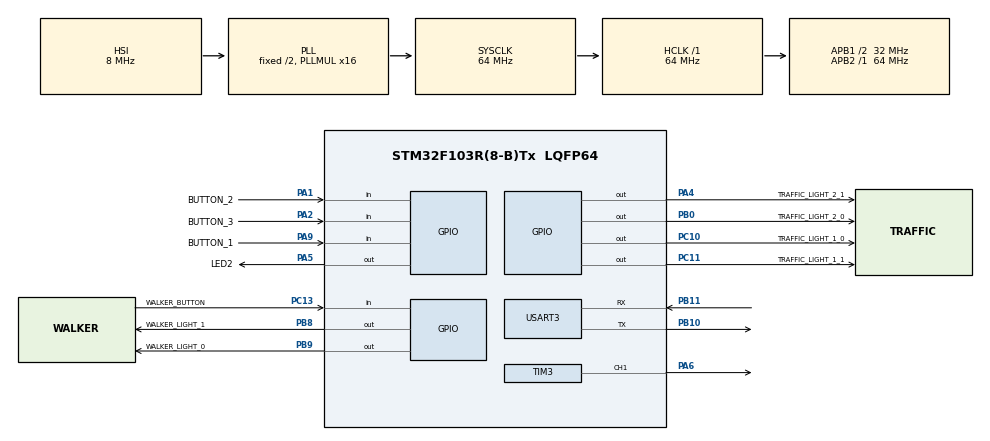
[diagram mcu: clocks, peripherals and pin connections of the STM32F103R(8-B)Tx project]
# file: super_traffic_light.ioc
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Mcu.Family=STM32F1
Mcu.Name=STM32F103R(8-B)Tx
Mcu.Package=LQFP64
NVIC.PriorityGroup=NVIC_PRIORITYGROUP_4
NVIC.TIM2_IRQn=true\:0\:0\:false\:false\:true\:true\:true
NVIC.USART3_IRQn=true\:0\:0\:false\:false\:true\:true\:true
PA1.GPIO_Label=BUTTON_2
PA1.Signal=GPIO_Input
PA13.Mode=Serial_Wire
PA13.Signal=SYS_JTMS-SWDIO
PA14.Mode=Serial_Wire
PA14.Signal=SYS_JTCK-SWCLK
PA2.GPIO_Label=BUTTON_3
PA2.Signal=GPIO_Input
PA4.GPIO_Label=TRAFFIC_LIGHT_2_1
PA4.Signal=GPIO_Output
PA5.GPIO_Label=LED2
PA5.Signal=GPIO_Output
PA6.Signal=S_TIM3_CH1
PA9.GPIO_Label=BUTTON_1
PA9.Signal=GPIO_Input
PB0.GPIO_Label=TRAFFIC_LIGHT_2_0
PB0.Signal=GPIO_Output
PB10.Mode=Asynchronous
PB10.Signal=USART3_TX
PB11.Mode=Asynchronous
PB11.Signal=USART3_RX
PB8.GPIO_Label=WALKER_LIGHT_1
PB8.Signal=GPIO_Output
PB9.GPIO_Label=WALKER_LIGHT_0
PB9.Signal=GPIO_Output
PC10.GPIO_Label=TRAFFIC_LIGHT_1_0
PC10.Signal=GPIO_Output
PC11.GPIO_Label=TRAFFIC_LIGHT_1_1
PC11.Signal=GPIO_Output
PC13-TAMPER-RTC.GPIO_Label=WALKER_BUTTON
PC13-TAMPER-RTC.Signal=GPIO_Input
PD0-OSC_IN.Mode=HSE-External-Oscillator
PD0-OSC_IN.Signal=RCC_OSC_IN
PD1-OSC_OUT.Mode=HSE-External-Oscillator
PD1-OSC_OUT.Signal=RCC_OSC_OUT
ProjectManager.HeapSize=0x200
ProjectManager.StackSize=0x400
ProjectManager.TargetToolchain=STM32CubeIDE
RCC.AHBFreq_Value=64000000
RCC.APB1CLKDivider=RCC_HCLK_DIV2
RCC.APB1Freq_Value=32000000
RCC.APB1TimFreq_Value=64000000
RCC.APB2Freq_Value=64000000
RCC.APB2TimFreq_Value=64000000
RCC.HCLKFreq_Value=64000000
RCC.PLLMUL=RCC_PLL_MUL16
RCC.SYSCLKFreq_VALUE=64000000
RCC.SYSCLKSource=RCC_SYSCLKSOURCE_PLLCLK
RCC.USBFreq_Value=64000000
SH.S_TIM3_CH1.0=TIM3_CH1,PWM Generation1 CH1
TIM2.CounterMode=TIM_COUNTERMODE_UP
TIM2.Period=999
TIM2.Prescaler=639
TIM3.Channel-PWM\ Generation1\ CH1=TIM_CHANNEL_1
TIM3.Period=999
TIM3.Prescaler=639
USART3.VirtualMode=VM_ASYNC
VP_TIM2_VS_ClockSourceINT.Mode=Internal
VP_TIM3_VS_ClockSourceINT.Mode=Internal
board=custom

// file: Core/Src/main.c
/* USER CODE BEGIN Header */
/**
  ******************************************************************************
  * @file           : main.c
  * @brief          : Main program body
  ******************************************************************************
  * @attention
  *
  * <h2><center>&copy; Copyright (c) 2023 STMicroelectronics.
  * All rights reserved.</center></h2>
  *
  * This software component is licensed by ST under BSD 3-Clause license,
  * the "License"; You may not use this file except in compliance with the
  * License. You may obtain a copy of the License at:
  *                        opensource.org/licenses/BSD-3-Clause
  *
  ******************************************************************************
  */
/* USER CODE END Header */
#include "main.h"

TIM_HandleTypeDef htim2;
TIM_HandleTypeDef htim3;

UART_HandleTypeDef huart3;

void SystemClock_Config(void);
static void MX_GPIO_Init(void);
static void MX_TIM2_Init(void);
static void MX_TIM3_Init(void);
static void MX_USART3_UART_Init(void);

int main(void)
{

  /* MCU Configuration--------------------------------------------------------*/

  /* Reset of all peripherals, Initializes the Flash interface and the Systick. */
  HAL_Init();

  /* USER CODE BEGIN Init */
timerInnit();
buttonInnit();
  /* USER CODE END Init */

  /* Configure the system clock */
  SystemClock_Config();

  /* Initialize all configured peripherals */
  MX_GPIO_Init();
  MX_TIM2_Init();
  MX_TIM3_Init();
  MX_USART3_UART_Init();
  /* USER CODE BEGIN 2 */
  HAL_TIM_Base_Start_IT (& htim2 );
  HAL_TIM_PWM_Start(&htim3, TIM_CHANNEL_1);
//  __HAL_UART_ENABLE_IT(&huart2, UART_IT_RXNE);

  /* USER CODE END 2 */

  /* Infinite loop */
  /* USER CODE BEGIN WHILE */
  while (1)
  {

	  fsm_manual_run();

    /* USER CODE END WHILE */

  }
}

void SystemClock_Config(void)
{
  RCC_OscInitTypeDef RCC_OscInitStruct = {0};
  RCC_ClkInitTypeDef RCC_ClkInitStruct = {0};

  /** Initializes the RCC Oscillators according to the specified parameters
  * in the RCC_OscInitTypeDef structure.
  */
  RCC_OscInitStruct.OscillatorType = RCC_OSCILLATORTYPE_HSI;
  RCC_OscInitStruct.HSIState = RCC_HSI_ON;
  RCC_OscInitStruct.HSICalibrationValue = RCC_HSICALIBRATION_DEFAULT;
  RCC_OscInitStruct.PLL.PLLState = RCC_PLL_ON;
  RCC_OscInitStruct.PLL.PLLSource = RCC_PLLSOURCE_HSI_DIV2;
  RCC_OscInitStruct.PLL.PLLMUL = RCC_PLL_MUL16;
  if (HAL_RCC_OscConfig(&RCC_OscInitStruct) != HAL_OK)
  {
    Error_Handler();
  }
  /** Initializes the CPU, AHB and APB buses clocks
  */
  RCC_ClkInitStruct.ClockType = RCC_CLOCKTYPE_HCLK|RCC_CLOCKTYPE_SYSCLK
                              |RCC_CLOCKTYPE_PCLK1|RCC_CLOCKTYPE_PCLK2;
  RCC_ClkInitStruct.SYSCLKSource = RCC_SYSCLKSOURCE_PLLCLK;
  RCC_ClkInitStruct.AHBCLKDivider = RCC_SYSCLK_DIV1;
  RCC_ClkInitStruct.APB1CLKDivider = RCC_HCLK_DIV2;
  RCC_ClkInitStruct.APB2CLKDivider = RCC_HCLK_DIV1;

  if (HAL_RCC_ClockConfig(&RCC_ClkInitStruct, FLASH_LATENCY_2) != HAL_OK)
  {
    Error_Handler();
  }
}

static void MX_TIM2_Init(void)
{

  TIM_ClockConfigTypeDef sClockSourceConfig = {0};
  TIM_MasterConfigTypeDef sMasterConfig = {0};

  htim2.Instance = TIM2;
  htim2.Init.Prescaler = 639;
  htim2.Init.CounterMode = TIM_COUNTERMODE_UP;
  htim2.Init.Period = 999;
  htim2.Init.ClockDivision = TIM_CLOCKDIVISION_DIV1;
  htim2.Init.AutoReloadPreload = TIM_AUTORELOAD_PRELOAD_DISABLE;
  if (HAL_TIM_Base_Init(&htim2) != HAL_OK)
  {
    Error_Handler();
  }
  sClockSourceConfig.ClockSource = TIM_CLOCKSOURCE_INTERNAL;
  if (HAL_TIM_ConfigClockSource(&htim2, &sClockSourceConfig) != HAL_OK)
  {
    Error_Handler();
  }
  sMasterConfig.MasterOutputTrigger = TIM_TRGO_RESET;
  sMasterConfig.MasterSlaveMode = TIM_MASTERSLAVEMODE_DISABLE;
  if (HAL_TIMEx_MasterConfigSynchronization(&htim2, &sMasterConfig) != HAL_OK)
  {
    Error_Handler();
  }

}

static void MX_TIM3_Init(void)
{

  TIM_ClockConfigTypeDef sClockSourceConfig = {0};
  TIM_MasterConfigTypeDef sMasterConfig = {0};
  TIM_OC_InitTypeDef sConfigOC = {0};

  htim3.Instance = TIM3;
  htim3.Init.Prescaler = 639;
  htim3.Init.CounterMode = TIM_COUNTERMODE_UP;
  htim3.Init.Period = 999;
  htim3.Init.ClockDivision = TIM_CLOCKDIVISION_DIV1;
  htim3.Init.AutoReloadPreload = TIM_AUTORELOAD_PRELOAD_DISABLE;
  if (HAL_TIM_Base_Init(&htim3) != HAL_OK)
  {
    Error_Handler();
  }
  sClockSourceConfig.ClockSource = TIM_CLOCKSOURCE_INTERNAL;
  if (HAL_TIM_ConfigClockSource(&htim3, &sClockSourceConfig) != HAL_OK)
  {
    Error_Handler();
  }
  if (HAL_TIM_PWM_Init(&htim3) != HAL_OK)
  {
    Error_Handler();
  }
  sMasterConfig.MasterOutputTrigger = TIM_TRGO_RESET;
  sMasterConfig.MasterSlaveMode = TIM_MASTERSLAVEMODE_DISABLE;
  if (HAL_TIMEx_MasterConfigSynchronization(&htim3, &sMasterConfig) != HAL_OK)
  {
    Error_Handler();
  }
  sConfigOC.OCMode = TIM_OCMODE_PWM1;
  sConfigOC.Pulse = 0;
  sConfigOC.OCPolarity = TIM_OCPOLARITY_HIGH;
  sConfigOC.OCFastMode = TIM_OCFAST_DISABLE;
  if (HAL_TIM_PWM_ConfigChannel(&htim3, &sConfigOC, TIM_CHANNEL_1) != HAL_OK)
  {
    Error_Handler();
  }
  HAL_TIM_MspPostInit(&htim3);

}

static void MX_USART3_UART_Init(void)
{

  huart3.Instance = USART3;
  huart3.Init.BaudRate = 115200;
  huart3.Init.WordLength = UART_WORDLENGTH_8B;
  huart3.Init.StopBits = UART_STOPBITS_1;
  huart3.Init.Parity = UART_PARITY_NONE;
  huart3.Init.Mode = UART_MODE_TX_RX;
  huart3.Init.HwFlowCtl = UART_HWCONTROL_NONE;
  huart3.Init.OverSampling = UART_OVERSAMPLING_16;
  if (HAL_UART_Init(&huart3) != HAL_OK)
  {
    Error_Handler();
  }

}

static void MX_GPIO_Init(void)
{
  GPIO_InitTypeDef GPIO_InitStruct = {0};

  /* GPIO Ports Clock Enable */
  __HAL_RCC_GPIOC_CLK_ENABLE();
  __HAL_RCC_GPIOD_CLK_ENABLE();
  __HAL_RCC_GPIOA_CLK_ENABLE();
  __HAL_RCC_GPIOB_CLK_ENABLE();

  /*Configure GPIO pin Output Level */
  HAL_GPIO_WritePin(GPIOA, TRAFFIC_LIGHT_2_1_Pin|LED2_Pin, GPIO_PIN_RESET);

  /*Configure GPIO pin Output Level */
  HAL_GPIO_WritePin(GPIOB, TRAFFIC_LIGHT_2_0_Pin|WALKER_LIGHT_1_Pin|WALKER_LIGHT_0_Pin, GPIO_PIN_RESET);

  /*Configure GPIO pin Output Level */
  HAL_GPIO_WritePin(GPIOC, TRAFFIC_LIGHT_1_0_Pin|TRAFFIC_LIGHT_1_1_Pin, GPIO_PIN_RESET);

  /*Configure GPIO pin : WALKER_BUTTON_Pin */
  GPIO_InitStruct.Pin = WALKER_BUTTON_Pin;
  GPIO_InitStruct.Mode = GPIO_MODE_INPUT;
  GPIO_InitStruct.Pull = GPIO_NOPULL;
  HAL_GPIO_Init(WALKER_BUTTON_GPIO_Port, &GPIO_InitStruct);

  /*Configure GPIO pins : BUTTON_2_Pin BUTTON_3_Pin BUTTON_1_Pin */
  GPIO_InitStruct.Pin = BUTTON_2_Pin|BUTTON_3_Pin|BUTTON_1_Pin;
  GPIO_InitStruct.Mode = GPIO_MODE_INPUT;
  GPIO_InitStruct.Pull = GPIO_NOPULL;
  HAL_GPIO_Init(GPIOA, &GPIO_InitStruct);

  /*Configure GPIO pins : TRAFFIC_LIGHT_2_1_Pin LED2_Pin */
  GPIO_InitStruct.Pin = TRAFFIC_LIGHT_2_1_Pin|LED2_Pin;
  GPIO_InitStruct.Mode = GPIO_MODE_OUTPUT_PP;
  GPIO_InitStruct.Pull = GPIO_NOPULL;
  GPIO_InitStruct.Speed = GPIO_SPEED_FREQ_LOW;
  HAL_GPIO_Init(GPIOA, &GPIO_InitStruct);

  /*Configure GPIO pins : TRAFFIC_LIGHT_2_0_Pin WALKER_LIGHT_1_Pin WALKER_LIGHT_0_Pin */
  GPIO_InitStruct.Pin = TRAFFIC_LIGHT_2_0_Pin|WALKER_LIGHT_1_Pin|WALKER_LIGHT_0_Pin;
  GPIO_InitStruct.Mode = GPIO_MODE_OUTPUT_PP;
  GPIO_InitStruct.Pull = GPIO_NOPULL;
  GPIO_InitStruct.Speed = GPIO_SPEED_FREQ_LOW;
  HAL_GPIO_Init(GPIOB, &GPIO_InitStruct);

  /*Configure GPIO pins : TRAFFIC_LIGHT_1_0_Pin TRAFFIC_LIGHT_1_1_Pin */
  GPIO_InitStruct.Pin = TRAFFIC_LIGHT_1_0_Pin|TRAFFIC_LIGHT_1_1_Pin;
  GPIO_InitStruct.Mode = GPIO_MODE_OUTPUT_PP;
  GPIO_InitStruct.Pull = GPIO_NOPULL;
  GPIO_InitStruct.Speed = GPIO_SPEED_FREQ_LOW;
  HAL_GPIO_Init(GPIOC, &GPIO_InitStruct);

}

/* USER CODE BEGIN 4 */
void HAL_TIM_PeriodElapsedCallback ( TIM_HandleTypeDef * htim ){
	  timerRun();
	  getKeyInput();

}
/* USER CODE END 4 */

void Error_Handler(void)
{
  __disable_irq();
  while (1)
  {
  }
}

/************************ (C) COPYRIGHT STMicroelectronics *****END OF FILE****/
